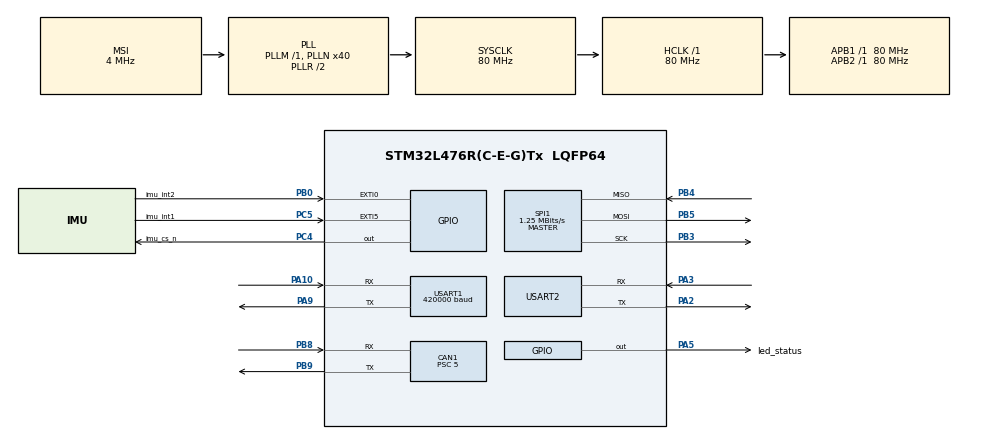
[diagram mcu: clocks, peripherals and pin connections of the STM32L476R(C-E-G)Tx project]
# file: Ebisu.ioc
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CAN1.ABOM=ENABLE
CAN1.BS1=CAN_BS1_14TQ
CAN1.CalculateBaudRate=1000000
CAN1.CalculateTimeBit=1000
CAN1.CalculateTimeQuantum=62.5
CAN1.NART=ENABLE
CAN1.Prescaler=5
CAN1.SJW=CAN_SJW_1TQ
Dma.Request0=USART1_RX
Dma.USART1_RX.0.Direction=DMA_PERIPH_TO_MEMORY
Dma.USART1_RX.0.Instance=DMA1_Channel5
Dma.USART1_RX.0.MemDataAlignment=DMA_MDATAALIGN_BYTE
Dma.USART1_RX.0.MemInc=DMA_MINC_ENABLE
Dma.USART1_RX.0.Mode=DMA_CIRCULAR
Dma.USART1_RX.0.PeriphDataAlignment=DMA_PDATAALIGN_BYTE
Dma.USART1_RX.0.PeriphInc=DMA_PINC_DISABLE
Dma.USART1_RX.0.Priority=DMA_PRIORITY_HIGH
FREERTOS.Tasks01=defaultTask,24,256,StartDefaultTask,Default,NULL,Dynamic,NULL,NULL
FREERTOS.configTOTAL_HEAP_SIZE=24576
Mcu.Family=STM32L4
Mcu.Name=STM32L476R(C-E-G)Tx
Mcu.Package=LQFP64
NVIC.CAN1_RX0_IRQn=true\:5\:0\:false\:false\:true\:true\:true\:true\:true
NVIC.CAN1_SCE_IRQn=true\:5\:0\:false\:false\:true\:true\:true\:true\:true
NVIC.DMA1_Channel5_IRQn=true\:5\:0\:false\:false\:true\:true\:false\:true\:true
NVIC.EXTI0_IRQn=true\:6\:0\:true\:false\:true\:false\:true\:true\:true
NVIC.EXTI9_5_IRQn=true\:6\:0\:true\:false\:true\:false\:true\:true\:true
NVIC.PriorityGroup=NVIC_PRIORITYGROUP_4
NVIC.TIM6_DAC_IRQn=true\:15\:0\:false\:false\:true\:false\:false\:true\:true
NVIC.TimeBase=TIM6_DAC_IRQn
NVIC.TimeBaseIP=TIM6
NVIC.USART1_IRQn=true\:6\:0\:true\:false\:true\:true\:true\:true\:true
NVIC.USART2_IRQn=true\:5\:0\:false\:false\:true\:true\:true\:true\:true
PA10.Mode=Asynchronous
PA10.Signal=USART1_RX
PA13\ (JTMS-SWDIO).Mode=Serial_Wire
PA13\ (JTMS-SWDIO).Signal=SYS_JTMS-SWDIO
PA14\ (JTCK-SWCLK).Mode=Serial_Wire
PA14\ (JTCK-SWCLK).Signal=SYS_JTCK-SWCLK
PA2.Mode=Asynchronous
PA2.Signal=USART2_TX
PA3.Mode=Asynchronous
PA3.Signal=USART2_RX
PA5.GPIO_Label=led_status
PA5.Signal=GPIO_Output
PA9.Mode=Asynchronous
PA9.Signal=USART1_TX
PB0.GPIO_Label=imu_int2
PB0.Signal=GPXTI0
PB3\ (JTDO-TRACESWO).Mode=Full_Duplex_Master
PB3\ (JTDO-TRACESWO).Signal=SPI1_SCK
PB4\ (NJTRST).Mode=Full_Duplex_Master
PB4\ (NJTRST).Signal=SPI1_MISO
PB5.Mode=Full_Duplex_Master
PB5.Signal=SPI1_MOSI
PB8.Mode=CAN_Activate
PB8.Signal=CAN1_RX
PB9.Mode=CAN_Activate
PB9.Signal=CAN1_TX
PC4.GPIO_Label=imu_cs_n
PC4.GPIO_Speed=GPIO_SPEED_FREQ_MEDIUM
PC4.PinState=GPIO_PIN_SET
PC4.Signal=GPIO_Output
PC5.GPIO_Label=imu_int1
PC5.Signal=GPXTI5
ProjectManager.HeapSize=0x400
ProjectManager.StackSize=0x1000
ProjectManager.TargetToolchain=CMake
RCC.ADCFreq_Value=16000000
RCC.AHBFreq_Value=80000000
RCC.APB1Freq_Value=80000000
RCC.APB1TimFreq_Value=80000000
RCC.APB2Freq_Value=80000000
RCC.APB2TimFreq_Value=80000000
RCC.CortexFreq_Value=80000000
RCC.HCLKFreq_Value=80000000
RCC.HSE_VALUE=8000000
RCC.HSI_VALUE=16000000
RCC.LSE_VALUE=32768
RCC.MSI_VALUE=4000000
RCC.PLLN=40
RCC.SYSCLKFreq_VALUE=80000000
RCC.SYSCLKSource=RCC_SYSCLKSOURCE_PLLCLK
RCC.USBFreq_Value=16000000
RCC.VCOOutputFreq_Value=160000000
SPI1.BaudRatePrescaler=SPI_BAUDRATEPRESCALER_64
SPI1.CLKPhase=SPI_PHASE_2EDGE
SPI1.CLKPolarity=SPI_POLARITY_HIGH
SPI1.CalculateBaudRate=1.25 MBits/s
SPI1.DataSize=SPI_DATASIZE_8BIT
SPI1.Direction=SPI_DIRECTION_2LINES
SPI1.Mode=SPI_MODE_MASTER
SPI1.VirtualType=VM_MASTER
TIM2.Prescaler=79
USART1.BaudRate=420000
USART1.VirtualMode-Asynchronous=VM_ASYNC
USART2.VirtualMode-Asynchronous=VM_ASYNC
VP_FREERTOS_VS_CMSIS_V2.Mode=CMSIS_V2
VP_SYS_VS_tim6.Mode=TIM6
VP_TIM2_VS_ClockSourceINT.Mode=Internal
board=custom

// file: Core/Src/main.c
/* USER CODE BEGIN Header */
/**
  ******************************************************************************
  * @file           : main.c
  * @brief          : Main program body
  ******************************************************************************
  * @attention
  *
  * Copyright (c) 2026 STMicroelectronics.
  * All rights reserved.
  *
  * This software is licensed under terms that can be found in the LICENSE file
  * in the root directory of this software component.
  * If no LICENSE file comes with this software, it is provided AS-IS.
  *
  ******************************************************************************
  */
/* USER CODE END Header */
#include "main.h"
#include "cmsis_os.h"
#include "can.h"
#include "dma.h"
#include "spi.h"
#include "tim.h"
#include "usart.h"
#include "gpio.h"

void SystemClock_Config(void);
void MX_FREERTOS_Init(void);

int main(void)
{

  /* MCU Configuration--------------------------------------------------------*/

  /* Reset of all peripherals, Initializes the Flash interface and the Systick. */
  HAL_Init();

  /* Configure the system clock */
  SystemClock_Config();

  /* Initialize all configured peripherals */
  MX_GPIO_Init();
  MX_DMA_Init();
  MX_CAN1_Init();
  MX_TIM2_Init();
  MX_USART2_UART_Init();
  MX_USART1_UART_Init();
  MX_SPI1_Init();
  /* USER CODE BEGIN 2 */
  if (HAL_TIM_Base_Start(&htim2) != HAL_OK)
  {
      Error_Handler();
  }
  /* USER CODE END 2 */

  /* Init scheduler */
  osKernelInitialize();  /* Call init function for freertos objects (in cmsis_os2.c) */
  MX_FREERTOS_Init();

  /* Start scheduler */
  osKernelStart();

  /* We should never get here as control is now taken by the scheduler */

  /* Infinite loop */
  while (1)
  {

  }
}

void SystemClock_Config(void)
{
  RCC_OscInitTypeDef RCC_OscInitStruct = {0};
  RCC_ClkInitTypeDef RCC_ClkInitStruct = {0};

  /** Configure the main internal regulator output voltage
  */
  if (HAL_PWREx_ControlVoltageScaling(PWR_REGULATOR_VOLTAGE_SCALE1) != HAL_OK)
  {
    Error_Handler();
  }

  /** Initializes the RCC Oscillators according to the specified parameters
  * in the RCC_OscInitTypeDef structure.
  */
  RCC_OscInitStruct.OscillatorType = RCC_OSCILLATORTYPE_MSI;
  RCC_OscInitStruct.MSIState = RCC_MSI_ON;
  RCC_OscInitStruct.MSICalibrationValue = 0;
  RCC_OscInitStruct.MSIClockRange = RCC_MSIRANGE_6;
  RCC_OscInitStruct.PLL.PLLState = RCC_PLL_ON;
  RCC_OscInitStruct.PLL.PLLSource = RCC_PLLSOURCE_MSI;
  RCC_OscInitStruct.PLL.PLLM = 1;
  RCC_OscInitStruct.PLL.PLLN = 40;
  RCC_OscInitStruct.PLL.PLLP = RCC_PLLP_DIV7;
  RCC_OscInitStruct.PLL.PLLQ = RCC_PLLQ_DIV2;
  RCC_OscInitStruct.PLL.PLLR = RCC_PLLR_DIV2;
  if (HAL_RCC_OscConfig(&RCC_OscInitStruct) != HAL_OK)
  {
    Error_Handler();
  }

  /** Initializes the CPU, AHB and APB buses clocks
  */
  RCC_ClkInitStruct.ClockType = RCC_CLOCKTYPE_HCLK|RCC_CLOCKTYPE_SYSCLK
                              |RCC_CLOCKTYPE_PCLK1|RCC_CLOCKTYPE_PCLK2;
  RCC_ClkInitStruct.SYSCLKSource = RCC_SYSCLKSOURCE_PLLCLK;
  RCC_ClkInitStruct.AHBCLKDivider = RCC_SYSCLK_DIV1;
  RCC_ClkInitStruct.APB1CLKDivider = RCC_HCLK_DIV1;
  RCC_ClkInitStruct.APB2CLKDivider = RCC_HCLK_DIV1;

  if (HAL_RCC_ClockConfig(&RCC_ClkInitStruct, FLASH_LATENCY_4) != HAL_OK)
  {
    Error_Handler();
  }
}

void HAL_TIM_PeriodElapsedCallback(TIM_HandleTypeDef *htim)
{
  if (htim->Instance == TIM6)
  {
    HAL_IncTick();
  }
}

void Error_Handler(void)
{
  __disable_irq();
  while (1)
  {
  }
}

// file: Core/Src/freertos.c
/* USER CODE BEGIN Header */
/**
  ******************************************************************************
  * File Name          : freertos.c
  * Description        : Code for freertos applications
  ******************************************************************************
  * @attention
  *
  * Copyright (c) 2026 STMicroelectronics.
  * All rights reserved.
  *
  * This software is licensed under terms that can be found in the LICENSE file
  * in the root directory of this software component.
  * If no LICENSE file comes with this software, it is provided AS-IS.
  *
  ******************************************************************************
  */
/* USER CODE END Header */

#include "FreeRTOS.h"
#include "task.h"
#include "main.h"
#include "cmsis_os.h"

/* USER CODE BEGIN Includes */
#include "test_bringup.h"
/* USER CODE END Includes */

/* Definitions for defaultTask */
osThreadId_t defaultTaskHandle;
const osThreadAttr_t defaultTask_attributes = {
  .name = "defaultTask",
  .stack_size = 256 * 4,
  .priority = (osPriority_t) osPriorityNormal,
};

void StartDefaultTask(void *argument);

void MX_FREERTOS_Init(void); /* (MISRA C 2004 rule 8.1) */

void MX_FREERTOS_Init(void) {

  /* Create the thread(s) */
  /* creation of defaultTask */
  defaultTaskHandle = osThreadNew(StartDefaultTask, NULL, &defaultTask_attributes);

  /* USER CODE BEGIN RTOS_THREADS */
  /* add threads, ... */
  test_bringup_start();
  /* USER CODE END RTOS_THREADS */

}

void StartDefaultTask(void *argument)
{
  for(;;)
  {
    osDelay(1);
  }
}
